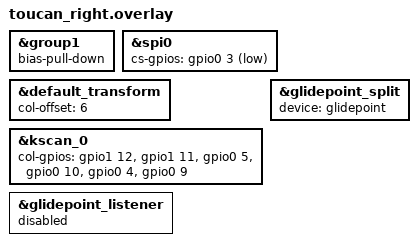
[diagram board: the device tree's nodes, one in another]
#include "toucan.dtsi"
#include "toucan_spi.dtsi"

&group1 {
    bias-pull-down; // minimize power leakage during sleep
};

&spi0 {
    cs-gpios = <&gpio0 3 (GPIO_ACTIVE_LOW | GPIO_PULL_UP)>;  // pull-up to ensure CS is !asserted when asleep
};

&default_transform {
    col-offset = <6>;
};

&kscan_0 {
    col-gpios
    = <&gpio1 12 GPIO_ACTIVE_HIGH>
    , <&gpio1 11 GPIO_ACTIVE_HIGH>
    , <&gpio0 5 GPIO_ACTIVE_HIGH>
    , <&gpio0 10 GPIO_ACTIVE_HIGH>
    , <&gpio0 4 GPIO_ACTIVE_HIGH>
    , <&gpio0 9 GPIO_ACTIVE_HIGH>
    ;
};

&glidepoint_listener {
    status = "disabled";
};

&glidepoint_split {
    status = "okay";
    device = <&glidepoint>;
};
